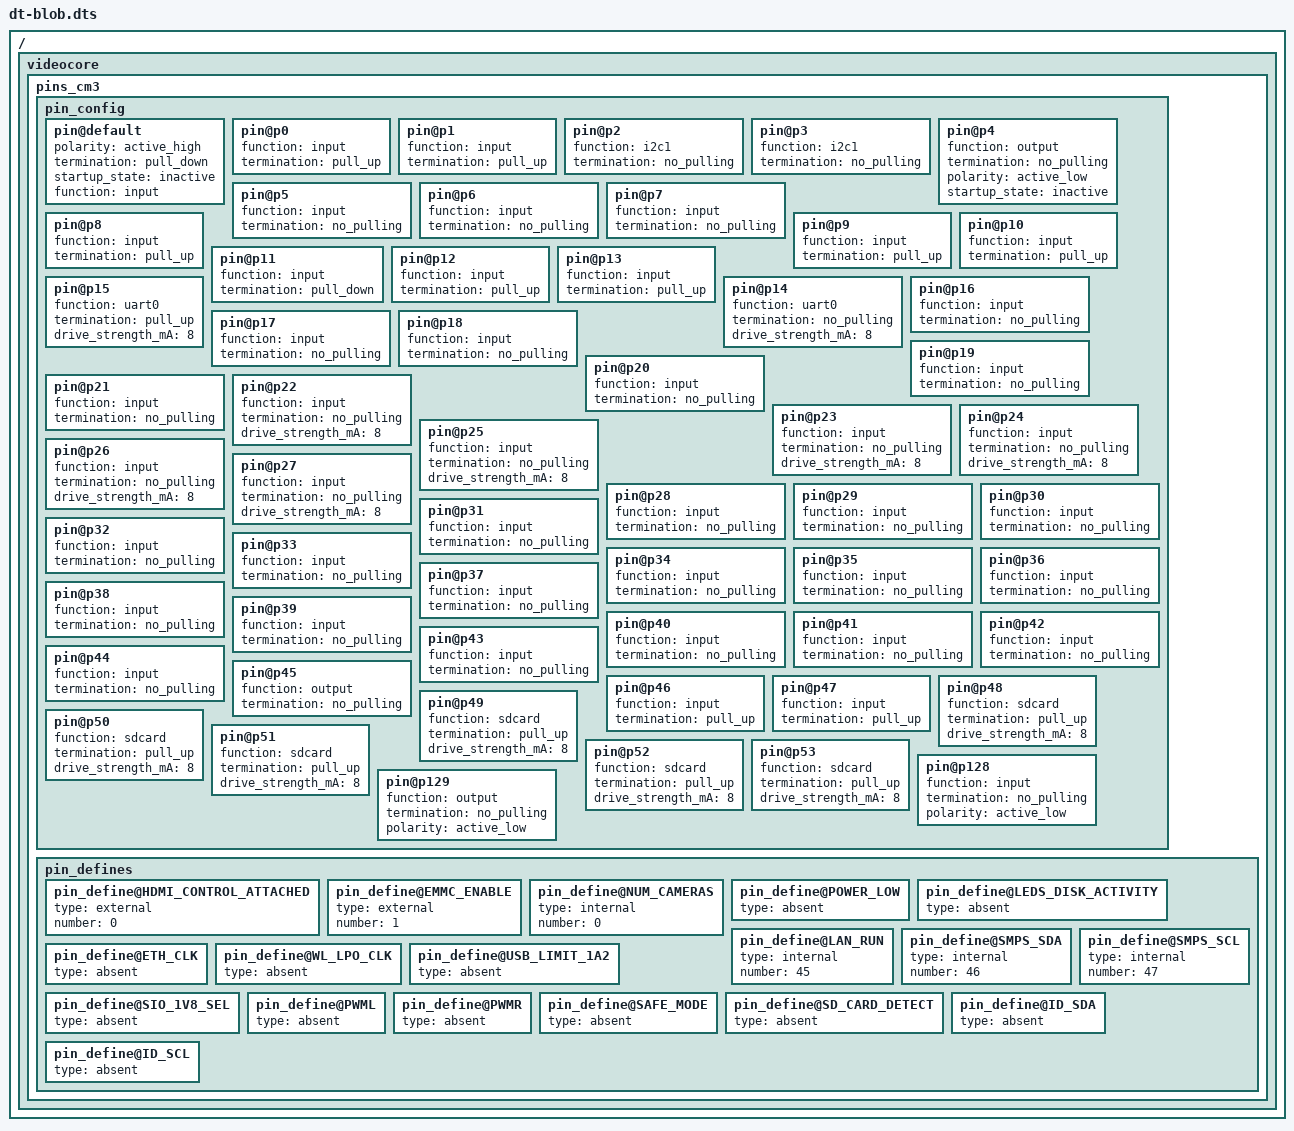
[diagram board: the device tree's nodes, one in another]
/dts-v1/;

/ {
  videocore {
    pins_cm3 {
      pin_config {
        pin@default {
          polarity = "active_high";
          termination = "pull_down";
          startup_state = "inactive";
          function = "input";
        }; // pin

        // BANK 0 - USER GPIO //
        pin@p0  { function = "input";   termination = "pull_up";    }; // unused
        pin@p1  { function = "input";   termination = "pull_up";    }; // unused
        pin@p2  { function = "i2c1";    termination = "no_pulling"; }; // I2C1 SDA
        pin@p3  { function = "i2c1";    termination = "no_pulling"; }; // I2C1 SCL
        pin@p4	{ function = "output";	termination = "no_pulling"; polarity = "active_low"; startup_state = "inactive";   }; // POWER_HOLD
        pin@p5  { function = "input";   termination = "no_pulling"; }; // C_STATUS_LED_N
        pin@p6  { function = "input";   termination = "no_pulling"; }; // CM_EE_WP
        pin@p7  { function = "input";   termination = "no_pulling"; }; // RTC_IRQ_N
        pin@p8  { function = "input";   termination = "pull_up";    }; // C_TRIGGER / debug
        pin@p9  { function = "input";   termination = "pull_up";    }; // debug
        pin@p10 { function = "input";   termination = "pull_up";    }; // LAN_PWR_N / debug
        pin@p11 { function = "input";   termination = "pull_down";  }; // LED_TEST
        pin@p12 { function = "input";   termination = "pull_up";    }; // debug
        pin@p13 { function = "input";   termination = "pull_up";    }; // debug
        pin@p14 { function = "uart0";   termination = "no_pulling"; drive_strength_mA = <8>; }; // UART TX
        pin@p15 { function = "uart0";   termination = "pull_up";    drive_strength_mA = <8>; }; // UART RX
        pin@p16 { function = "input";   termination = "no_pulling"; }; // BUTTON_0
        pin@p17 { function = "input";   termination = "no_pulling"; }; // BUTTON_1
        pin@p18 { function = "input";   termination = "no_pulling"; }; // RESET_BUTTON
        pin@p19 { function = "input";   termination = "no_pulling"; }; // SD_PWR_N
        pin@p20 { function = "input";   termination = "no_pulling"; }; // SD_DET
        pin@p21 { function = "input";   termination = "no_pulling"; }; // SD_WP
        pin@p22 { function = "input";   termination = "no_pulling"; drive_strength_mA = <8>; }; // SD_CLK
        pin@p23 { function = "input";   termination = "no_pulling"; drive_strength_mA = <8>; }; // SD_CMD
        pin@p24 { function = "input";   termination = "no_pulling"; drive_strength_mA = <8>; }; // SD_D0
        pin@p25 { function = "input";   termination = "no_pulling"; drive_strength_mA = <8>; }; // SD_D1
        pin@p26 { function = "input";   termination = "no_pulling"; drive_strength_mA = <8>; }; // SD_D2
        pin@p27 { function = "input";   termination = "no_pulling"; drive_strength_mA = <8>; }; // SD_D3

        // BANK 1 - USER GPIO//
        pin@p28 { function = "input";   termination = "no_pulling"; }; // LED_0_G
        pin@p29 { function = "input";   termination = "no_pulling"; }; // LED_0_Y
        pin@p30 { function = "input";   termination = "no_pulling"; }; // LED_1_G
        pin@p31 { function = "input";   termination = "no_pulling"; }; // LED_1_Y
        pin@p32 { function = "input";   termination = "no_pulling"; }; // LED_2_G
        pin@p33 { function = "input";   termination = "no_pulling"; }; // LED_2_Y
        pin@p34 { function = "input";   termination = "no_pulling"; }; // LED_3_G
        pin@p35 { function = "input";   termination = "no_pulling"; }; // LED_3_Y
        pin@p36 { function = "input";   termination = "no_pulling"; }; // DIN_0
        pin@p37 { function = "input";   termination = "no_pulling"; }; // DIN_1
        pin@p38 { function = "input";   termination = "no_pulling"; }; // DIN_2
        pin@p39 { function = "input";   termination = "no_pulling"; }; // DIN_3
        pin@p40 { function = "input";   termination = "no_pulling"; }; // DOUT_0
        pin@p41 { function = "input";   termination = "no_pulling"; }; // DOUT_1
        pin@p42 { function = "input";   termination = "no_pulling"; }; // DOUT_2
        pin@p43 { function = "input";   termination = "no_pulling"; }; // DOUT_3
        pin@p44 { function = "input";   termination = "no_pulling"; }; // LAN_CLOCK
        pin@p45 { function = "output";  termination = "no_pulling"; }; // LAN_RUN

        // BANK 2 - DON'T TOUCH UNLESS YOU KNOW WHAT YOU'RE DOING //
        pin@p46 { function = "input";   termination = "pull_up"; }; // SMPS_SCL
        pin@p47 { function = "input";   termination = "pull_up"; }; // SMPS_SDA
        pin@p48 { function = "sdcard";  termination = "pull_up";    drive_strength_mA = <8>; }; // eMMC CLK
        pin@p49 { function = "sdcard";  termination = "pull_up";    drive_strength_mA = <8>; }; // eMMC CMD
        pin@p50 { function = "sdcard";  termination = "pull_up";    drive_strength_mA = <8>; }; // eMMC D0
        pin@p51 { function = "sdcard";  termination = "pull_up";    drive_strength_mA = <8>; }; // eMMC D1
        pin@p52 { function = "sdcard";  termination = "pull_up";    drive_strength_mA = <8>; }; // eMMC D2
        pin@p53 { function = "sdcard";  termination = "pull_up";    drive_strength_mA = <8>; }; // eMMC D3
        pin@p128 { function = "input";  termination = "no_pulling"; polarity = "active_low"; }; // Hotplug
        pin@p129 { function = "output"; termination = "no_pulling"; polarity = "active_low"; }; // EMMC_ENABLE_N

      }; // pin_config

      pin_defines {
        pin_define@HDMI_CONTROL_ATTACHED {
            type = "external";
            number = <0>;
        };
        pin_define@EMMC_ENABLE {
            type = "external";
            number = <1>;
        };
        pin_define@NUM_CAMERAS {
            type = "internal";
            number = <0>;
        };
        pin_define@POWER_LOW {
            type = "absent";
        };
        pin_define@LEDS_DISK_ACTIVITY {
            type = "absent";
        };
        pin_define@LAN_RUN {
            type = "internal";
            number = <45>;
        };
        pin_define@SMPS_SDA {
            type = "internal";
            number = <46>;
        };
        pin_define@SMPS_SCL {
            type = "internal";
            number = <47>;
        };
        pin_define@ETH_CLK {
            type = "absent";
        };
        pin_define@WL_LPO_CLK {
            type = "absent";
        };
        pin_define@USB_LIMIT_1A2 {
            type = "absent";
        };
        pin_define@SIO_1V8_SEL {
            type = "absent";
        };
        pin_define@PWML {
            type = "absent";
        };
        pin_define@PWMR {
            type = "absent";
        };
        pin_define@SAFE_MODE {
            type = "absent";
        };
        pin_define@SD_CARD_DETECT {
            type = "absent";
        };
        pin_define@ID_SDA {
            type = "absent";
        };
        pin_define@ID_SCL {
            type = "absent";
        };
      }; // pin_defines
    }; // pins_cm3

  }; // videocore
};


